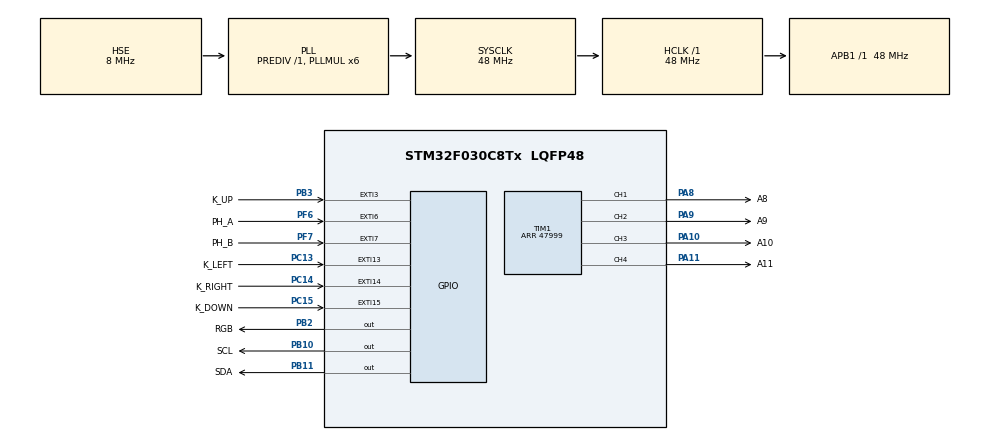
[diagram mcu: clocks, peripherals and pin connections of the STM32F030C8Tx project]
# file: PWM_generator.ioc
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Mcu.Family=STM32F0
Mcu.Name=STM32F030C8Tx
Mcu.Package=LQFP48
NVIC.EXTI2_3_IRQn=true\:0\:0\:true\:false\:true\:true\:true\:true
NVIC.EXTI4_15_IRQn=true\:0\:0\:false\:false\:true\:true\:true\:true
PA10.GPIO_Label=A10
PA10.GPIO_Speed=GPIO_SPEED_FREQ_HIGH
PA10.Signal=S_TIM1_CH3
PA11.GPIO_Label=A11
PA11.GPIO_Speed=GPIO_SPEED_FREQ_HIGH
PA11.Signal=S_TIM1_CH4
PA13.Mode=Serial_Wire
PA13.Signal=SYS_SWDIO
PA14.Mode=Serial_Wire
PA14.Signal=SYS_SWCLK
PA8.GPIO_Label=A8
PA8.GPIO_Speed=GPIO_SPEED_FREQ_HIGH
PA8.Signal=S_TIM1_CH1
PA9.GPIO_Label=A9
PA9.GPIO_Speed=GPIO_SPEED_FREQ_HIGH
PA9.Signal=S_TIM1_CH2
PB10.GPIO_Label=SCL
PB10.GPIO_ModeDefaultOutputPP=GPIO_MODE_OUTPUT_PP
PB10.GPIO_PuPd=GPIO_PULLUP
PB10.GPIO_Speed=GPIO_SPEED_FREQ_LOW
PB10.PinState=GPIO_PIN_SET
PB10.Signal=GPIO_Output
PB11.GPIO_Label=SDA
PB11.GPIO_ModeDefaultOutputPP=GPIO_MODE_OUTPUT_PP
PB11.GPIO_PuPd=GPIO_PULLUP
PB11.GPIO_Speed=GPIO_SPEED_FREQ_LOW
PB11.PinState=GPIO_PIN_SET
PB11.Signal=GPIO_Output
PB2.GPIO_Label=RGB
PB2.GPIO_ModeDefaultOutputPP=GPIO_MODE_OUTPUT_PP
PB2.GPIO_PuPd=GPIO_PULLUP
PB2.GPIO_Speed=GPIO_SPEED_FREQ_HIGH
PB2.PinState=GPIO_PIN_SET
PB2.Signal=GPIO_Output
PB3.GPIO_Label=K_UP
PB3.GPIO_ModeDefaultEXTI=GPIO_MODE_IT_FALLING
PB3.GPIO_PuPd=GPIO_PULLUP
PB3.Signal=GPXTI3
PC13.GPIO_Label=K_LEFT
PC13.GPIO_ModeDefaultEXTI=GPIO_MODE_IT_FALLING
PC13.GPIO_PuPd=GPIO_PULLUP
PC13.Signal=GPXTI13
PC14-OSC32_IN.GPIO_Label=K_RIGHT
PC14-OSC32_IN.GPIO_ModeDefaultEXTI=GPIO_MODE_IT_FALLING
PC14-OSC32_IN.GPIO_PuPd=GPIO_PULLUP
PC14-OSC32_IN.Signal=GPXTI14
PC15-OSC32_OUT.GPIO_Label=K_DOWN
PC15-OSC32_OUT.GPIO_ModeDefaultEXTI=GPIO_MODE_IT_FALLING
PC15-OSC32_OUT.GPIO_PuPd=GPIO_PULLUP
PC15-OSC32_OUT.Signal=GPXTI15
PF0-OSC_IN.Mode=HSE-External-Oscillator
PF0-OSC_IN.Signal=RCC_OSC_IN
PF1-OSC_OUT.Mode=HSE-External-Oscillator
PF1-OSC_OUT.Signal=RCC_OSC_OUT
PF6.GPIO_Label=PH_A
PF6.GPIO_ModeDefaultEXTI=GPIO_MODE_IT_RISING_FALLING
PF6.GPIO_PuPd=GPIO_PULLUP
PF6.Signal=GPXTI6
PF7.GPIO_Label=PH_B
PF7.GPIO_ModeDefaultEXTI=GPIO_MODE_IT_RISING_FALLING
PF7.GPIO_PuPd=GPIO_PULLUP
PF7.Signal=GPXTI7
ProjectManager.HeapSize=0x200
ProjectManager.StackSize=0x400
ProjectManager.TargetToolchain=MDK-ARM V5.32
RCC.AHBFreq_Value=48000000
RCC.APB1Freq_Value=48000000
RCC.APB1TimFreq_Value=48000000
RCC.HCLKFreq_Value=48000000
RCC.PLLMUL=RCC_PLL_MUL6
RCC.PLLSourceVirtual=RCC_PLLSOURCE_HSE
RCC.SYSCLKFreq_VALUE=48000000
RCC.SYSCLKSource=RCC_SYSCLKSOURCE_PLLCLK
SH.S_TIM1_CH1.0=TIM1_CH1,PWM Generation1 CH1
SH.S_TIM1_CH2.0=TIM1_CH2,PWM Generation2 CH2
SH.S_TIM1_CH3.0=TIM1_CH3,PWM Generation3 CH3
SH.S_TIM1_CH4.0=TIM1_CH4,PWM Generation4 CH4
TIM1.AutoReloadPreload=TIM_AUTORELOAD_PRELOAD_ENABLE
TIM1.Channel-PWM\ Generation1\ CH1=TIM_CHANNEL_1
TIM1.Channel-PWM\ Generation2\ CH2=TIM_CHANNEL_2
TIM1.Channel-PWM\ Generation3\ CH3=TIM_CHANNEL_3
TIM1.Channel-PWM\ Generation4\ CH4=TIM_CHANNEL_4
TIM1.Period=47999
VP_TIM1_VS_ClockSourceINT.Mode=Internal
board=custom

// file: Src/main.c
/* USER CODE BEGIN Header */
/**
  ******************************************************************************
  * @file           : main.c
  * @brief          : Main program body
  ******************************************************************************
  * @attention
  *
  * Copyright (c) 2022 STMicroelectronics.
  * All rights reserved.
  *
  * This software is licensed under terms that can be found in the LICENSE file
  * in the root directory of this software component.
  * If no LICENSE file comes with this software, it is provided AS-IS.
  *
  ******************************************************************************
  */
/* USER CODE END Header */
#include "main.h"
#include "tim.h"
#include "gpio.h"

/* USER CODE BEGIN Includes */
#include "OLED.h"
#include "WS2812.h"
/* USER CODE END Includes */

void SystemClock_Config(void);

int main(void)
{

  /* MCU Configuration--------------------------------------------------------*/

  /* Reset of all peripherals, Initializes the Flash interface and the Systick. */
  HAL_Init();

  /* Configure the system clock */
  SystemClock_Config();

  /* Initialize all configured peripherals */
  MX_GPIO_Init();
  MX_TIM1_Init();
  /* USER CODE BEGIN 2 */
 HAL_TIM_PWM_Start(&htim1,TIM_CHANNEL_1);
 __HAL_TIM_SetCompare(&htim1,TIM_CHANNEL_1,20000);
  OLED_Init();
   OLED_ShowString(1,1,"OLED");

  /* USER CODE END 2 */

  /* Infinite loop */
  while (1)
  {

  }
}

void SystemClock_Config(void)
{
  RCC_OscInitTypeDef RCC_OscInitStruct = {0};
  RCC_ClkInitTypeDef RCC_ClkInitStruct = {0};

  /** Initializes the RCC Oscillators according to the specified parameters
  * in the RCC_OscInitTypeDef structure.
  */
  RCC_OscInitStruct.OscillatorType = RCC_OSCILLATORTYPE_HSE;
  RCC_OscInitStruct.HSEState = RCC_HSE_ON;
  RCC_OscInitStruct.PLL.PLLState = RCC_PLL_ON;
  RCC_OscInitStruct.PLL.PLLSource = RCC_PLLSOURCE_HSE;
  RCC_OscInitStruct.PLL.PLLMUL = RCC_PLL_MUL6;
  RCC_OscInitStruct.PLL.PREDIV = RCC_PREDIV_DIV1;
  if (HAL_RCC_OscConfig(&RCC_OscInitStruct) != HAL_OK)
  {
    Error_Handler();
  }

  /** Initializes the CPU, AHB and APB buses clocks
  */
  RCC_ClkInitStruct.ClockType = RCC_CLOCKTYPE_HCLK|RCC_CLOCKTYPE_SYSCLK
                              |RCC_CLOCKTYPE_PCLK1;
  RCC_ClkInitStruct.SYSCLKSource = RCC_SYSCLKSOURCE_PLLCLK;
  RCC_ClkInitStruct.AHBCLKDivider = RCC_SYSCLK_DIV1;
  RCC_ClkInitStruct.APB1CLKDivider = RCC_HCLK_DIV1;

  if (HAL_RCC_ClockConfig(&RCC_ClkInitStruct, FLASH_LATENCY_1) != HAL_OK)
  {
    Error_Handler();
  }
}

void Error_Handler(void)
{
  __disable_irq();
  while (1)
  {
  }
}
